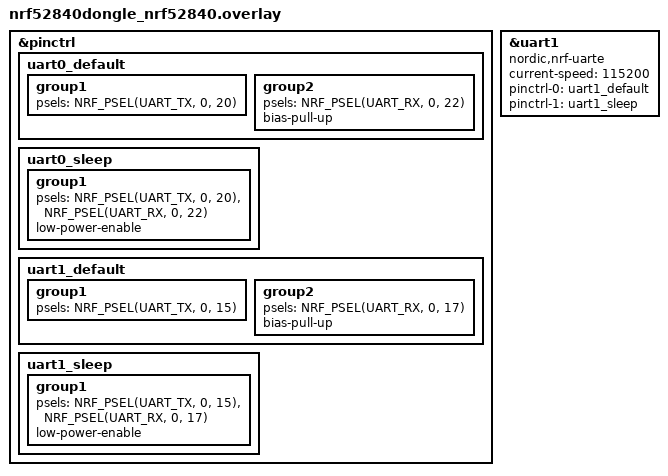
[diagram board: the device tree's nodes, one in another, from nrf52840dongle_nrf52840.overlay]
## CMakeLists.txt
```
cmake_minimum_required(VERSION 3.20.0)

add_compile_options(-fdiagnostics-color=always)
add_compile_options(-Wall)
#add_compile_options(-Werror)

find_package(Zephyr REQUIRED HINTS $ENV{ZEPHYR_BASE})
project(radio_tx)

target_sources(app PRIVATE src/main.c src/tx_radio.c src/tx_uart.c src/common/radio.c)
```

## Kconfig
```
source "Kconfig.zephyr"

menu "Serial Radio: Transmitter"

config RADIO_TX_APP_LOG_LEVEL
	int "Log level for the radio_tx"
	default 4

config RADIO_GPIO_ENABLE_SW
	bool "Utilize GPIO as enable switch for primary channel transmit."
	default false

endmenu
```

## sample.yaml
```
sample:
  description: Serial Radio Transmitter
  name: radio_tx
common:
    tags: introduction
    integration_platforms:
      - native_posix
    harness: console
    harness_config:
      type: one_line
      regex:
        - "Hello World! (.*)"
tests:
  sample.basic.helloworld:
    tags: introduction
```

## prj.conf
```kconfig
CONFIG_DEBUG_THREAD_INFO=n
CONFIG_DEBUG_OPTIMIZATIONS=n

CONFIG_GPIO=y
CONFIG_NFCT_PINS_AS_GPIOS=y

CONFIG_LOG=n
CONFIG_CONSOLE=n

CONFIG_SERIAL=y
CONFIG_UART_ASYNC_API=y
CONFIG_UART_0_NRF_HW_ASYNC=y
# TIMER2 is apparently used by the ESB library.
CONFIG_UART_0_NRF_HW_ASYNC_TIMER=1
CONFIG_UART_1_NRF_HW_ASYNC=y
# TIMER2 is apparently used by the ESB library.
CONFIG_UART_1_NRF_HW_ASYNC_TIMER=3

CONFIG_ESB=y
CONFIG_ESB_TX_FIFO_SIZE=1
CONFIG_ESB_RX_FIFO_SIZE=2
CONFIG_ESB_MAX_PAYLOAD_LENGTH=252

CONFIG_PIPES=y

CONFIG_MPSL=y
CONFIG_MPSL_FEM_ONLY=y
```

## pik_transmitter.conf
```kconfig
CONFIG_RADIO_GPIO_ENABLE_SW=y
```

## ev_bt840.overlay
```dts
/ {
  inputs: inputs {
    compatible = "gpio-keys";
    tx_enable_sw: enable_sw {
      gpios = <&gpio0 11 (GPIO_PULL_UP | GPIO_ACTIVE_LOW)>;
      label = "Enable switch for primary TX.";
    };
  };
};
```

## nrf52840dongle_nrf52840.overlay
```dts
&pinctrl {
	uart0_default: uart0_default {
		group1 {
			psels = <NRF_PSEL(UART_TX, 0, 20)>;
		};
		group2 {
			psels = <NRF_PSEL(UART_RX, 0, 22)>;
			bias-pull-up;
		};
	};

	uart0_sleep: uart0_sleep {
		group1 {
			psels = <NRF_PSEL(UART_TX, 0, 20)>,
				<NRF_PSEL(UART_RX, 0, 22)>;
			low-power-enable;
		};
	};

	uart1_default: uart1_default {
		group1 {
			psels = <NRF_PSEL(UART_TX, 0, 15)>;
		};
		group2 {
			psels = <NRF_PSEL(UART_RX, 0, 17)>;
			bias-pull-up;
		};
	};

	uart1_sleep: uart1_sleep {
		group1 {
			psels = <NRF_PSEL(UART_TX, 0, 15)>,
				<NRF_PSEL(UART_RX, 0, 17)>;
			low-power-enable;
		};
	};
};

&uart1 {
	compatible = "nordic,nrf-uarte";
	status = "okay";
	current-speed = <115200>;
	pinctrl-0 = <&uart1_default>;
	pinctrl-1 = <&uart1_sleep>;
	pinctrl-names = "default", "sleep";
};
```

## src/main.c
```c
#include <zephyr/kernel.h>
#include <zephyr/logging/log.h>

LOG_MODULE_REGISTER(main, CONFIG_RADIO_TX_APP_LOG_LEVEL);

#include "common/leds.h"
#include "tx_radio.h"
#include "tx_uart.h"

// RX Pipe defines
#define RX_PIPE_SIZE 2048

// Thread defines
#define THREAD_NUM 4
#define THREAD_STACK_SIZE 512
#define THREAD_UART_PRIORITY 10
#define THREAD_RADIO_PRIORITY 20
#define THREAD_MAIN_PRIORITY 30

// Data channel defines
#define NUM_CHANNELS 2

typedef struct {
  const char *name;
  struct k_thread *thread_data;
  k_thread_stack_t *stack;
  size_t stack_size;
  k_thread_entry_t entry;
  void *entry_arg1;
  void *entry_arg2;
  void *entry_arg3;
  int priority;
  uint32_t options;
  k_timeout_t delay;
} ThreadConfig;

// Static state for application / threads.
K_PIPE_DEFINE(g_pipe_0, RX_PIPE_SIZE, 1);
K_PIPE_DEFINE(g_pipe_1, RX_PIPE_SIZE, 1);
static struct k_pipe *const g_pipes[NUM_CHANNELS] = {&g_pipe_0, &g_pipe_1};

static UartState g_uart_state[NUM_CHANNELS];
static RadioState g_radio_state[NUM_CHANNELS];

K_THREAD_STACK_ARRAY_DEFINE(g_thread_stacks, THREAD_NUM, THREAD_STACK_SIZE);
static struct k_thread g_thread_data[THREAD_NUM];

void main(void) {
  LOG_INF("Starting TX radio...");

  if (SetupLeds() < 0) {
    return;
  };

  if (RadioInit() < 0) {
    return;
  }

  const UartConfig uart_configs[NUM_CHANNELS] = {
      {
          .uart = DEVICE_DT_GET(DT_NODELABEL(uart0)),
          .baud = 921600,
          .rx_timeout_us = 500,
          .output_pipe = g_pipes[0],
          .primary = true,
      },
      {
          .uart = DEVICE_DT_GET(DT_NODELABEL(uart1)),
          .baud = 921600,
          .rx_timeout_us = 500,
          .output_pipe = g_pipes[1],
          .primary = false,
      },
  };

  const RadioTxConfig radio_configs[NUM_CHANNELS] = {
      {
          .input_data_pipe = g_pipes[0],
          .radio_tx_pipe = 0,
      },
      {
          .input_data_pipe = g_pipes[1],
          .radio_tx_pipe = 1,
      },
  };

  k_tid_t threads[THREAD_NUM];
  const ThreadConfig thread_configs[THREAD_NUM] = {
      {
          .name = "Uart0",
          .thread_data = &g_thread_data[0],
          .stack = g_thread_stacks[0],
          .stack_size = K_THREAD_STACK_SIZEOF(g_thread_stacks[0]),
          .entry = (k_thread_entry_t)UartRxThread,
          .entry_arg1 = (void *)&uart_configs[0],
          .entry_arg2 = &g_uart_state[0],
          .entry_arg3 = NULL,
          .priority = THREAD_UART_PRIORITY + 0,
          .options = 0,
          .delay = K_NO_WAIT,
      },
      {
          .name = "Uart1",
          .thread_data = &g_thread_data[1],
          .stack = g_thread_stacks[1],
          .stack_size = K_THREAD_STACK_SIZEOF(g_thread_stacks[1]),
          .entry = (k_thread_entry_t)UartRxThread,
          .entry_arg1 = (void *)&uart_configs[1],
          .entry_arg2 = &g_uart_state[1],
          .entry_arg3 = NULL,
          .priority = THREAD_UART_PRIORITY + 1,
          .options = 0,
          .delay = K_NO_WAIT,
      },
      {
          .name = "Radio0",
          .thread_data = &g_thread_data[2],
          .stack = g_thread_stacks[2],
          .stack_size = K_THREAD_STACK_SIZEOF(g_thread_stacks[2]),
          .entry = (k_thread_entry_t)RadioTxThread,
          .entry_arg1 = (void *)&radio_configs[0],
          .entry_arg2 = &g_radio_state[0],
          .entry_arg3 = NULL,
          .priority = THREAD_RADIO_PRIORITY + 0,
          .options = 0,
          .delay = K_NO_WAIT,
      },
      {
          .name = "Radio1",
          .thread_data = &g_thread_data[3],
          .stack = g_thread_stacks[3],
          .stack_size = K_THREAD_STACK_SIZEOF(g_thread_stacks[3]),
          .entry = (k_thread_entry_t)RadioTxThread,
          .entry_arg1 = (void *)&radio_configs[1],
          .entry_arg2 = &g_radio_state[1],
          .entry_arg3 = NULL,
          .priority = THREAD_RADIO_PRIORITY + 1,
          .options = 0,
          .delay = K_NO_WAIT,
      },
  };

  for (int i = 0; i < THREAD_NUM; ++i) {
    const ThreadConfig *const c = &thread_configs[i];
    threads[i] = k_thread_create(c->thread_data, c->stack, c->stack_size, c->entry, c->entry_arg1,
                                 c->entry_arg2, c->entry_arg3, c->priority, c->options, c->delay);
    k_thread_name_set(threads[i], c->name);
  }

  // Set priority to background allowing other threads to start.
  k_thread_priority_set(k_current_get(), THREAD_MAIN_PRIORITY);

  bool running_led = false;
  while (true) {
    k_msleep(500);

    // Toggle running LED.
    running_led = !running_led;
    SetLed(LED_RUNNING, running_led);

    // Set error LED based on state of threads.
    bool error_status = false;
    error_status = error_status || RadioGetGlobalErrorStatus();
    error_status = error_status || RadioGetErrorStatus(&g_radio_state[0]);
    error_status = error_status || RadioGetErrorStatus(&g_radio_state[1]);
    error_status = error_status || UartGetErrorStatus(&g_uart_state[0]);
    error_status = error_status || UartGetErrorStatus(&g_uart_state[1]);

    SetLed(LED_ERROR, error_status);

    // If any threads exit, toggle error LED indefinitely.
    for (int i = 0; i < THREAD_NUM; ++i) {
      int ret = k_thread_join(thread_configs[i].thread_data, K_NO_WAIT);
      while (ret == 0) {
        SetLed(LED_ERROR, true);
        k_msleep(500);
        SetLed(LED_ERROR, false);
        k_msleep(500);
      }
    }
  }
}
```

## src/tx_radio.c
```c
#include "tx_radio.h"

#include <string.h>

#include <esb.h>
#include <zephyr/kernel.h>
#include <zephyr/logging/log.h>

LOG_MODULE_REGISTER(tx_radio, CONFIG_LOG_LEVEL_DEFAULT);

#include "common/leds.h"
#include "common/radio.h"

typedef struct {
  atomic_t tx_failed;
  atomic_t tx_multiple_callbacks;
  atomic_t other;
} RadioHandlerErrors;

typedef struct {
  struct k_sem tx_sem;  // Semaphore indicating TX FIFO is available.
  atomic_t tx_failed_flag;  // Flag indicating TX failed and FIFO should be flushed.
  atomic_t tx_attempts;  // Total TX attempts.
  atomic_t tx_pkts;  // Total successful packets.
  RadioHandlerErrors errors;
  atomic_t initialized;
} RadioGlobalState;

static RadioGlobalState g_radio_state;

static void EsbHandler(const struct esb_evt *event) {
  switch (event->evt_id) {
    case ESB_EVENT_TX_FAILED:
      atomic_set(&g_radio_state.tx_failed_flag, true);
      atomic_inc(&g_radio_state.errors.tx_failed);

    // Fall through intended.
    case ESB_EVENT_TX_SUCCESS:
      atomic_add(&g_radio_state.tx_attempts, event->tx_attempts);
      atomic_inc(&g_radio_state.tx_pkts);

      if (k_sem_count_get(&g_radio_state.tx_sem) != 0) {
        atomic_inc(&g_radio_state.errors.tx_multiple_callbacks);
      }
      k_sem_give(&g_radio_state.tx_sem);

      // Signal transmission finished.
      SetLed(LED_RADIO_STATUS, false);
      break;
    case ESB_EVENT_RX_RECEIVED:
      atomic_inc(&g_radio_state.errors.other);
      break;
  }
}

static int RadioStateInit(RadioState *state, uint8_t pipe) {
  if (pipe > RADIO_NUM_PIPES) {
    LOG_ERR("Pipe number out of range.");
    return -1;
  }

  state->tx_payload.pipe = pipe;
  state->tx_payload.noack = false;
  state->tx_write_index = 0;

  memset(&state->stats, 0, sizeof(state->stats));

  return 0;
}

static int ReadSingleByte(RadioState *state, struct k_pipe *pipe, k_timeout_t timeout) {
  const size_t bytes_to_read = RADIO_MAX_PKT_LEN - state->tx_write_index;
  if (bytes_to_read == 0) return 0;

  uint8_t *const write_ptr = state->tx_payload.data + state->tx_write_index;

  size_t bytes_read = 0;
  const int ret = k_pipe_get(pipe, write_ptr, 1, &bytes_read, 1, timeout);
  state->tx_write_index += bytes_read;

  return ret;
}

static int ReadAllAvailable(RadioState *state, struct k_pipe *pipe) {
  const size_t bytes_to_read = RADIO_MAX_PKT_LEN - state->tx_write_index;
  if (bytes_to_read == 0) return 0;

  uint8_t *const write_ptr = state->tx_payload.data + state->tx_write_index;

  size_t bytes_read = 0;
  const int ret = k_pipe_get(pipe, write_ptr, bytes_to_read, &bytes_read, 0, K_NO_WAIT);
  state->tx_write_index += bytes_read;

  return ret;
}

int RadioInit(void) {
  if (SetupEsb(ESB_MODE_PTX, EsbHandler) < 0) return -1;

  // Radio TX FIFO is set to 1.
  if (k_sem_init(&g_radio_state.tx_sem, 1, 1) < 0) return -1;

  atomic_set(&g_radio_state.tx_failed_flag, false);

  memset(&g_radio_state.errors, 0, sizeof(g_radio_state.errors));

  atomic_set(&g_radio_state.initialized, true);
  return 0;
}

bool RadioGetGlobalErrorStatus(void) {
  bool status = false;
  status = status || atomic_get(&g_radio_state.errors.tx_multiple_callbacks);
  status = status || atomic_get(&g_radio_state.errors.other);

  return status;
}

bool RadioGetErrorStatus(const RadioState *state) {
  bool status = false;
  status = status || atomic_get(&state->stats.errors.other);

  return status;
}

void RadioTxThread(const RadioTxConfig *config, RadioState *state, void *unused_3) {
  if (!atomic_get(&g_radio_state.initialized)) {
    LOG_ERR("Radio not initialized. Terminating.");
    return;
  }

  if(RadioStateInit(state, config->radio_tx_pipe) < 0) {
    return;
  }

  while (true) {
    // Only wait on data from pipe if there is nothing in the tx payload.
    if (state->tx_write_index == 0) {
      if (ReadSingleByte(state, config->input_data_pipe, K_FOREVER) < 0) {
        atomic_inc(&state->stats.errors.other);
        continue;
      }
    }

    // Wait on access to radio TX FIFO.
    if (k_sem_take(&g_radio_state.tx_sem, K_FOREVER) < 0) {
      atomic_inc(&state->stats.errors.other);
      continue;
    }

    // Read any newly available data into payload without waiting.
    if (ReadAllAvailable(state, config->input_data_pipe) < 0) {
      atomic_inc(&state->stats.errors.other);
    }

    // If a failed transmit has occurred flush the TX FIFO and clear the flag.
    if (atomic_clear(&g_radio_state.tx_failed_flag)) {
      esb_flush_tx();
    }

    // Place payload into TX FIFO.
    state->tx_payload.length = state->tx_write_index;
    int ret = esb_write_payload(&state->tx_payload);
    if (ret == 0) {
      atomic_inc(&state->stats.tx_pkts);
      state->tx_write_index = 0;
    } else {
      atomic_inc(&state->stats.errors.other);
    }

    // Signal transmission ongoing.
    SetLed(LED_RADIO_STATUS, true);
  }
}
```

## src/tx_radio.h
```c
#pragma once

#include <esb.h>
#include <zephyr/kernel.h>

typedef struct {
  struct {
    atomic_t other;
  } errors;
  atomic_t tx_pkts;
} RadioStats;

typedef struct {
  struct esb_payload tx_payload;
  uint32_t tx_write_index;
  RadioStats stats;
} RadioState;

typedef struct {
  struct k_pipe *input_data_pipe;  // Input byte pipe.
  uint8_t radio_tx_pipe;  // ESB pipe for outgoing payloads.
} RadioTxConfig;

int RadioInit(void);
void RadioTxThread(const RadioTxConfig *config, RadioState *state, void *unused_3);
bool RadioGetGlobalErrorStatus(void);
bool RadioGetErrorStatus(const RadioState *state);
```

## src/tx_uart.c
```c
#include "tx_uart.h"

#include <string.h>

#include <zephyr/drivers/gpio.h>
#include <zephyr/drivers/uart.h>
#include <zephyr/kernel.h>
#include <zephyr/logging/log.h>

LOG_MODULE_REGISTER(tx_uart, CONFIG_LOG_LEVEL_DEFAULT);

#include "common/leds.h"

static int UartEnable(UartState *state) {
  return uart_rx_enable(state->config->uart, state->rx_bufs[state->write_buf_index],
                        UART_RX_BUF_LEN, state->config->rx_timeout_us);
}

static void UartCallback(const struct device *uart, struct uart_event *event, UartState *state) {
  switch (event->type) {
    case UART_RX_DISABLED:
      atomic_inc(&state->stats.errors.rx_disabled);
      // Fall through intended.
    case UART_RX_BUF_REQUEST:
      if (++state->write_buf_index >= UART_RX_NUM_BUFS) {
        state->write_buf_index = 0;
      }

      uint8_t *const next_buf = state->rx_bufs[state->write_buf_index];

      // Next buffer is being updated to what was last read in uart thread indicating an overrun is
      // possible. Purge event queue and skip over what is currently being read.  Note this will
      // also occur when a deluge of RX_DISABLE events arrive.
      if (next_buf == atomic_ptr_get(&state->read_buf)) {
        atomic_inc(&state->stats.errors.isr_overflow);
        k_msgq_purge(&state->rx_event_queue);
      }

      if (event->type == UART_RX_BUF_REQUEST) {
        const int ret = uart_rx_buf_rsp(uart, next_buf, UART_RX_BUF_LEN);
        // -EBUSY is sometimes returned after a restart due to UART_RX_DISABLED.
        if (ret < 0 && ret != -EBUSY) {
          atomic_inc(&state->stats.errors.other);
        }
      } else {
        UartEnable(state);
      }

      break;
    case UART_RX_RDY:
      atomic_add(&state->stats.rx_bytes, event->data.rx.len);
      if (k_msgq_put(&state->rx_event_queue, &event->data.rx, K_NO_WAIT) < 0) {
        atomic_inc(&state->stats.errors.queue_overflow);
        k_msgq_purge(&state->rx_event_queue);
      }
      break;
    case UART_RX_STOPPED:
      atomic_inc(&state->stats.errors.rx_stopped);
      break;
    case UART_TX_DONE:
    case UART_TX_ABORTED:
      atomic_inc(&state->stats.errors.other);
      break;
    case UART_RX_BUF_RELEASED:
      break;
  }
}

static int UartInit(const UartConfig *config, UartState *state) {
  state->config = config;

  state->write_buf_index = 0;
  state->read_buf = NULL;

  k_msgq_init(&state->rx_event_queue, (uint8_t *)state->_rx_event_queue_buf,
              sizeof(state->_rx_event_queue_buf[0]), ARRAY_SIZE(state->_rx_event_queue_buf));

  memset(&state->stats, 0, sizeof(state->stats));

// Setup enable switch GPIO.
#ifdef CONFIG_RADIO_GPIO_ENABLE_SW
  const struct gpio_dt_spec enable_sw = GPIO_DT_SPEC_GET(DT_NODELABEL(tx_enable_sw), gpios);

  if (!gpio_is_ready_dt(&enable_sw)) {
    LOG_ERR("Enable switch port not ready.");
    return -1;
  }

  if (gpio_pin_configure_dt(&enable_sw, GPIO_INPUT) < 0) {
    LOG_ERR("Could not set enable switch to input.");
    return -1;
  }
#endif

  const struct uart_config uart_config = {
      .baudrate = config->baud,
      .parity = UART_CFG_PARITY_NONE,
      .stop_bits = UART_CFG_STOP_BITS_1,
      .data_bits = UART_CFG_DATA_BITS_8,
      .flow_ctrl = UART_CFG_FLOW_CTRL_NONE,
  };

  if (!device_is_ready(config->uart)) {
    LOG_ERR("Could not get uart.");
    return -1;
  }

  if (uart_configure(config->uart, &uart_config) < 0) {
    LOG_ERR("Could not configure uart.");
    return -1;
  }

  if (uart_callback_set(config->uart, (uart_callback_t)UartCallback, state) < 0) {
    LOG_ERR("Could not set uart callback.");
    return -1;
  }

  if (UartEnable(state) < 0) {
    LOG_ERR("Could not enable uart rx.");
    return -1;
  }

  return 0;
}

bool UartGetErrorStatus(const UartState *state) {
  bool status = false;
  status = status || atomic_get(&state->stats.errors.isr_overflow);
  status = status || atomic_get(&state->stats.errors.queue_overflow);
  status = status || atomic_get(&state->stats.errors.other);

  return status;
}

void UartRxThread(const UartConfig *config, UartState *state, void *unused3) {
  if (UartInit(config, state) < 0) return;

  while (true) {
    // Wait on rx event queue.
    struct uart_event_rx event;
    if (k_msgq_get(&state->rx_event_queue, &event, K_FOREVER) < 0) {
      atomic_inc(&state->stats.errors.other);
      continue;
    }

    // Signal to ISR what buffer is currently being read.
    atomic_ptr_set(&state->read_buf, event.buf);

#ifdef CONFIG_RADIO_GPIO_ENABLE_SW
    // Discard buffer if this is the primary channel and switch is not enabled.
    const struct gpio_dt_spec enable_sw = GPIO_DT_SPEC_GET(DT_NODELABEL(tx_enable_sw), gpios);
    if (config->primary && gpio_pin_get_dt(&enable_sw) != 1) {
      continue;
    }
#endif

    // If pipe can't accept bytes flush it.
    if (k_pipe_write_avail(config->output_pipe) < event.len) {
      k_pipe_flush(config->output_pipe);
      atomic_inc(&state->stats.errors.pipe_overflow);
    }

    // Write data into pipe.
    size_t bytes_written;
    if (k_pipe_put(config->output_pipe, event.buf + event.offset, event.len, &bytes_written,
                   event.len, K_NO_WAIT) < 0) {
      atomic_inc(&state->stats.errors.other);
    }
  }
}
```

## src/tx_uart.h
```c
#pragma once

#include <zephyr/drivers/uart.h>
#include <zephyr/kernel.h>

#include "common/radio.h"

#define UART_RX_NUM_BUFS 4
#define UART_RX_BUF_LEN RADIO_MAX_PKT_LEN
#define UART_RX_EVENT_QUEUE_LEN 16

BUILD_ASSERT(UART_RX_NUM_BUFS >= 4, "Must have at least 4 buffers.");

typedef struct {
  const struct device *uart;
  uint32_t baud;
  int32_t rx_timeout_us;
  struct k_pipe *output_pipe;
  bool primary;
} UartConfig;

typedef struct {
  struct {
    atomic_t isr_overflow;
    atomic_t queue_overflow;
    atomic_t pipe_overflow;
    atomic_t rx_stopped;
    atomic_t rx_disabled;
    atomic_t other;
  } errors;
  atomic_t rx_bytes;
} UartStats;

typedef struct {
  uint8_t rx_bufs[UART_RX_NUM_BUFS][UART_RX_BUF_LEN];
  uint32_t write_buf_index;
  atomic_ptr_t read_buf;

  struct uart_event_rx _rx_event_queue_buf[UART_RX_EVENT_QUEUE_LEN];
  struct k_msgq rx_event_queue;

  const UartConfig *config;
  UartStats stats;
} UartState;

void UartRxThread(const UartConfig *config, UartState *state, void *unused3);
bool UartGetErrorStatus(const UartState *state);
```
